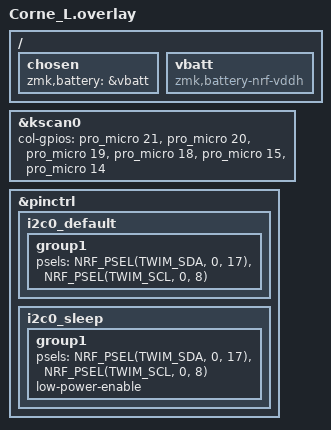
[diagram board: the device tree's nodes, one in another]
/*
 * Copyright (c) 2020 Pete Johanson
 *
 * SPDX-License-Identifier: MIT
 */

#include "Corne.dtsi"

&kscan0 {
    col-gpios
		= <&pro_micro 21 GPIO_ACTIVE_HIGH>
		, <&pro_micro 20 GPIO_ACTIVE_HIGH>
		, <&pro_micro 19 GPIO_ACTIVE_HIGH>
		, <&pro_micro 18 GPIO_ACTIVE_HIGH>
		, <&pro_micro 15 GPIO_ACTIVE_HIGH>
		, <&pro_micro 14 GPIO_ACTIVE_HIGH>
		;
};

&pinctrl {
	i2c0_default: i2c0_default {
		group1 {
			psels = <NRF_PSEL(TWIM_SDA, 0, 17)>,
							<NRF_PSEL(TWIM_SCL, 0, 8)>;
		};
	};

	i2c0_sleep: i2c0_sleep {
		group1 {
			psels = <NRF_PSEL(TWIM_SDA, 0, 17)>,
							<NRF_PSEL(TWIM_SCL, 0, 8)>;
			low-power-enable;
		};
	};
};

/ {
    chosen {
      zmk,battery = &vbatt;
    };

    vbatt: vbatt {
        compatible = "zmk,battery-nrf-vddh";
    };
};
